# MSS_CTRL_MSS_CTRL register map
Vendor: Texas Instruments
Registers are 32-bit, read-only, reset 0x0 unless marked. A register's access mark holds for its fields unless they carry their own. Offsets are as the file gives them; [hi:lo] are bit positions; {n}, {i} and the like mark numbered series.

## MSS_CTRL_MSS_CTRL (part 5 of 5)
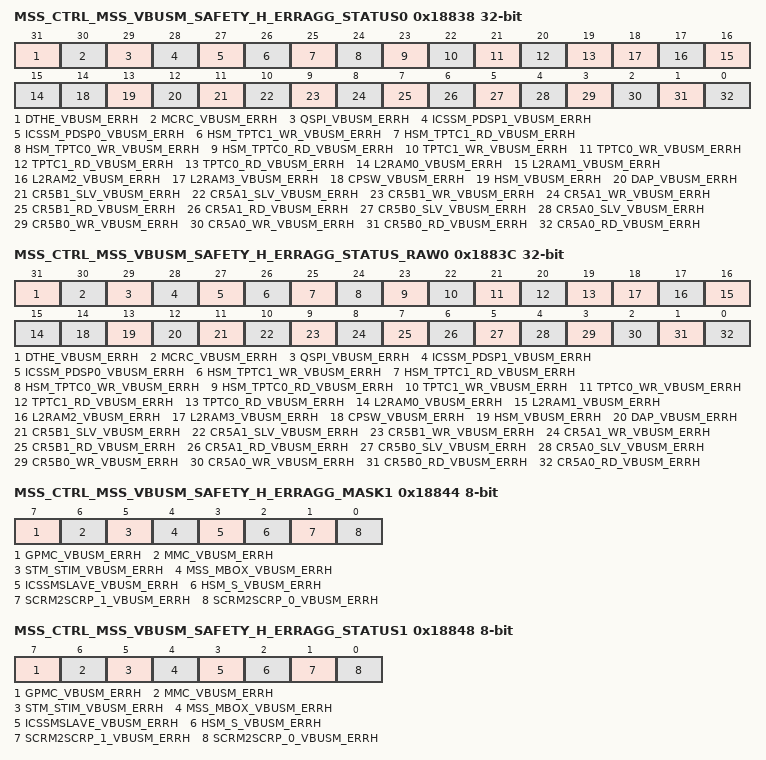
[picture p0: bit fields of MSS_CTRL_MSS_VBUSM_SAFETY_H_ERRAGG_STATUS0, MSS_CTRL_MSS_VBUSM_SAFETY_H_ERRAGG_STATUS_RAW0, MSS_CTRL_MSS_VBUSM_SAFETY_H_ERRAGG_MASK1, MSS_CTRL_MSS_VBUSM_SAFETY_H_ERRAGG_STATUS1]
0x18838 MSS_CTRL_MSS_VBUSM_SAFETY_H_ERRAGG_STATUS0 rw
  [31] DTHE_VBUSM_ERRH — Status of Error from MSS_VBUSM_SAFETY_H0_ERRAGG. Set only if Interupt is unmasked in MSS_VBUSM_SAFETY_H0_ERRAGG_ERRAGG_MASKWrie 0x1 to clear this Error.
  [30] MCRC_VBUSM_ERRH — Status of Error from MSS_VBUSM_SAFETY_H0_ERRAGG. Set only if Interupt is unmasked in MSS_VBUSM_SAFETY_H0_ERRAGG_ERRAGG_MASKWrie 0x1 to clear this Error.
  [29] QSPI_VBUSM_ERRH — Status of Error from MSS_VBUSM_SAFETY_H0_ERRAGG. Set only if Interupt is unmasked in MSS_VBUSM_SAFETY_H0_ERRAGG_ERRAGG_MASKWrie 0x1 to clear this Error.
  [28] ICSSM_PDSP1_VBUSM_ERRH — Status of Error from MSS_VBUSM_SAFETY_H0_ERRAGG. Set only if Interupt is unmasked in MSS_VBUSM_SAFETY_H0_ERRAGG_ERRAGG_MASKWrie 0x1 to clear this Error.
  [27] ICSSM_PDSP0_VBUSM_ERRH — Status of Error from MSS_VBUSM_SAFETY_H0_ERRAGG. Set only if Interupt is unmasked in MSS_VBUSM_SAFETY_H0_ERRAGG_ERRAGG_MASKWrie 0x1 to clear this Error.
  [26] HSM_TPTC1_WR_VBUSM_ERRH — Status of Error from MSS_VBUSM_SAFETY_H0_ERRAGG. Set only if Interupt is unmasked in MSS_VBUSM_SAFETY_H0_ERRAGG_ERRAGG_MASKWrie 0x1 to clear this Error.
  [25] HSM_TPTC1_RD_VBUSM_ERRH — Status of Error from MSS_VBUSM_SAFETY_H0_ERRAGG. Set only if Interupt is unmasked in MSS_VBUSM_SAFETY_H0_ERRAGG_ERRAGG_MASKWrie 0x1 to clear this Error.
  [24] HSM_TPTC0_WR_VBUSM_ERRH — Status of Error from MSS_VBUSM_SAFETY_H0_ERRAGG. Set only if Interupt is unmasked in MSS_VBUSM_SAFETY_H0_ERRAGG_ERRAGG_MASKWrie 0x1 to clear this Error.
  [23] HSM_TPTC0_RD_VBUSM_ERRH — Status of Error from MSS_VBUSM_SAFETY_H0_ERRAGG. Set only if Interupt is unmasked in MSS_VBUSM_SAFETY_H0_ERRAGG_ERRAGG_MASKWrie 0x1 to clear this Error.
  [22] TPTC1_WR_VBUSM_ERRH — Status of Error from MSS_VBUSM_SAFETY_H0_ERRAGG. Set only if Interupt is unmasked in MSS_VBUSM_SAFETY_H0_ERRAGG_ERRAGG_MASKWrie 0x1 to clear this Error.
  [21] TPTC0_WR_VBUSM_ERRH — Status of Error from MSS_VBUSM_SAFETY_H0_ERRAGG. Set only if Interupt is unmasked in MSS_VBUSM_SAFETY_H0_ERRAGG_ERRAGG_MASKWrie 0x1 to clear this Error.
  [20] TPTC1_RD_VBUSM_ERRH — Status of Error from MSS_VBUSM_SAFETY_H0_ERRAGG. Set only if Interupt is unmasked in MSS_VBUSM_SAFETY_H0_ERRAGG_ERRAGG_MASKWrie 0x1 to clear this Error.
  [19] TPTC0_RD_VBUSM_ERRH — Status of Error from MSS_VBUSM_SAFETY_H0_ERRAGG. Set only if Interupt is unmasked in MSS_VBUSM_SAFETY_H0_ERRAGG_ERRAGG_MASKWrie 0x1 to clear this Error.
  [n+15] L2RAM{n}_VBUSM_ERRH (n=0..3) — Status of Error from MSS_VBUSM_SAFETY_H0_ERRAGG. Set only if Interupt is unmasked in MSS_VBUSM_SAFETY_H0_ERRAGG_ERRAGG_MASKWrie 0x1 to clear this Error.
  [14] CPSW_VBUSM_ERRH — Status of Error from MSS_VBUSM_SAFETY_H0_ERRAGG. Set only if Interupt is unmasked in MSS_VBUSM_SAFETY_H0_ERRAGG_ERRAGG_MASKWrie 0x1 to clear this Error.
  [13] HSM_VBUSM_ERRH — Status of Error from MSS_VBUSM_SAFETY_H0_ERRAGG. Set only if Interupt is unmasked in MSS_VBUSM_SAFETY_H0_ERRAGG_ERRAGG_MASKWrie 0x1 to clear this Error.
  [12] DAP_VBUSM_ERRH — Status of Error from MSS_VBUSM_SAFETY_H0_ERRAGG. Set only if Interupt is unmasked in MSS_VBUSM_SAFETY_H0_ERRAGG_ERRAGG_MASKWrie 0x1 to clear this Error.
  [11] CR5B1_SLV_VBUSM_ERRH — Status of Error from MSS_VBUSM_SAFETY_H0_ERRAGG. Set only if Interupt is unmasked in MSS_VBUSM_SAFETY_H0_ERRAGG_ERRAGG_MASKWrie 0x1 to clear this Error.
  [10] CR5A1_SLV_VBUSM_ERRH — Status of Error from MSS_VBUSM_SAFETY_H0_ERRAGG. Set only if Interupt is unmasked in MSS_VBUSM_SAFETY_H0_ERRAGG_ERRAGG_MASKWrie 0x1 to clear this Error.
  [9] CR5B1_WR_VBUSM_ERRH — Status of Error from MSS_VBUSM_SAFETY_H0_ERRAGG. Set only if Interupt is unmasked in MSS_VBUSM_SAFETY_H0_ERRAGG_ERRAGG_MASKWrie 0x1 to clear this Error.
  [8] CR5A1_WR_VBUSM_ERRH — Status of Error from MSS_VBUSM_SAFETY_H0_ERRAGG. Set only if Interupt is unmasked in MSS_VBUSM_SAFETY_H0_ERRAGG_ERRAGG_MASKWrie 0x1 to clear this Error.
  [7] CR5B1_RD_VBUSM_ERRH — Status of Error from MSS_VBUSM_SAFETY_H0_ERRAGG. Set only if Interupt is unmasked in MSS_VBUSM_SAFETY_H0_ERRAGG_ERRAGG_MASKWrie 0x1 to clear this Error.
  [6] CR5A1_RD_VBUSM_ERRH — Status of Error from MSS_VBUSM_SAFETY_H0_ERRAGG. Set only if Interupt is unmasked in MSS_VBUSM_SAFETY_H0_ERRAGG_ERRAGG_MASKWrie 0x1 to clear this Error.
  [5] CR5B0_SLV_VBUSM_ERRH — Status of Error from MSS_VBUSM_SAFETY_H0_ERRAGG. Set only if Interupt is unmasked in MSS_VBUSM_SAFETY_H0_ERRAGG_ERRAGG_MASKWrie 0x1 to clear this Error.
  [4] CR5A0_SLV_VBUSM_ERRH — Status of Error from MSS_VBUSM_SAFETY_H0_ERRAGG. Set only if Interupt is unmasked in MSS_VBUSM_SAFETY_H0_ERRAGG_ERRAGG_MASKWrie 0x1 to clear this Error.
  [3] CR5B0_WR_VBUSM_ERRH — Status of Error from MSS_VBUSM_SAFETY_H0_ERRAGG. Set only if Interupt is unmasked in MSS_VBUSM_SAFETY_H0_ERRAGG_ERRAGG_MASKWrie 0x1 to clear this Error.
  [2] CR5A0_WR_VBUSM_ERRH — Status of Error from MSS_VBUSM_SAFETY_H0_ERRAGG. Set only if Interupt is unmasked in MSS_VBUSM_SAFETY_H0_ERRAGG_ERRAGG_MASKWrie 0x1 to clear this Error.
  [1] CR5B0_RD_VBUSM_ERRH — Status of Error from MSS_VBUSM_SAFETY_H0_ERRAGG. Set only if Interupt is unmasked in MSS_VBUSM_SAFETY_H0_ERRAGG_ERRAGG_MASKWrie 0x1 to clear this Error.
  [0] CR5A0_RD_VBUSM_ERRH — Status of Error from MSS_VBUSM_SAFETY_H0_ERRAGG. Set only if Interupt is unmasked in MSS_VBUSM_SAFETY_H0_ERRAGG_ERRAGG_MASKWrie 0x1 to clear this Error.
0x1883C MSS_CTRL_MSS_VBUSM_SAFETY_H_ERRAGG_STATUS_RAW0 rw
  [31] DTHE_VBUSM_ERRH — Raw Status of Error from MSS_VBUSM_SAFETY_H0_ERRAGG. Set irrespective if the Interupt is masked or unmasked in MSS_VBUSM_SAFETY_H0_ERRAGG_ERRAGG_MASK
  [30] MCRC_VBUSM_ERRH — Raw Status of Error from MSS_VBUSM_SAFETY_H0_ERRAGG. Set irrespective if the Interupt is masked or unmasked in MSS_VBUSM_SAFETY_H0_ERRAGG_ERRAGG_MASK
  [29] QSPI_VBUSM_ERRH — Raw Status of Error from MSS_VBUSM_SAFETY_H0_ERRAGG. Set irrespective if the Interupt is masked or unmasked in MSS_VBUSM_SAFETY_H0_ERRAGG_ERRAGG_MASK
  [28] ICSSM_PDSP1_VBUSM_ERRH — Raw Status of Error from MSS_VBUSM_SAFETY_H0_ERRAGG. Set irrespective if the Interupt is masked or unmasked in MSS_VBUSM_SAFETY_H0_ERRAGG_ERRAGG_MASK
  [27] ICSSM_PDSP0_VBUSM_ERRH — Raw Status of Error from MSS_VBUSM_SAFETY_H0_ERRAGG. Set irrespective if the Interupt is masked or unmasked in MSS_VBUSM_SAFETY_H0_ERRAGG_ERRAGG_MASK
  [26] HSM_TPTC1_WR_VBUSM_ERRH — Raw Status of Error from MSS_VBUSM_SAFETY_H0_ERRAGG. Set irrespective if the Interupt is masked or unmasked in MSS_VBUSM_SAFETY_H0_ERRAGG_ERRAGG_MASK
  [25] HSM_TPTC1_RD_VBUSM_ERRH — Raw Status of Error from MSS_VBUSM_SAFETY_H0_ERRAGG. Set irrespective if the Interupt is masked or unmasked in MSS_VBUSM_SAFETY_H0_ERRAGG_ERRAGG_MASK
  [24] HSM_TPTC0_WR_VBUSM_ERRH — Raw Status of Error from MSS_VBUSM_SAFETY_H0_ERRAGG. Set irrespective if the Interupt is masked or unmasked in MSS_VBUSM_SAFETY_H0_ERRAGG_ERRAGG_MASK
  [23] HSM_TPTC0_RD_VBUSM_ERRH — Raw Status of Error from MSS_VBUSM_SAFETY_H0_ERRAGG. Set irrespective if the Interupt is masked or unmasked in MSS_VBUSM_SAFETY_H0_ERRAGG_ERRAGG_MASK
  [22] TPTC1_WR_VBUSM_ERRH — Raw Status of Error from MSS_VBUSM_SAFETY_H0_ERRAGG. Set irrespective if the Interupt is masked or unmasked in MSS_VBUSM_SAFETY_H0_ERRAGG_ERRAGG_MASK
  [21] TPTC0_WR_VBUSM_ERRH — Raw Status of Error from MSS_VBUSM_SAFETY_H0_ERRAGG. Set irrespective if the Interupt is masked or unmasked in MSS_VBUSM_SAFETY_H0_ERRAGG_ERRAGG_MASK
  [20] TPTC1_RD_VBUSM_ERRH — Raw Status of Error from MSS_VBUSM_SAFETY_H0_ERRAGG. Set irrespective if the Interupt is masked or unmasked in MSS_VBUSM_SAFETY_H0_ERRAGG_ERRAGG_MASK
  [19] TPTC0_RD_VBUSM_ERRH — Raw Status of Error from MSS_VBUSM_SAFETY_H0_ERRAGG. Set irrespective if the Interupt is masked or unmasked in MSS_VBUSM_SAFETY_H0_ERRAGG_ERRAGG_MASK
  [n+15] L2RAM{n}_VBUSM_ERRH (n=0..3) — Raw Status of Error from MSS_VBUSM_SAFETY_H0_ERRAGG. Set irrespective if the Interupt is masked or unmasked in MSS_VBUSM_SAFETY_H0_ERRAGG_ERRAGG_MASK
  [14] CPSW_VBUSM_ERRH — Raw Status of Error from MSS_VBUSM_SAFETY_H0_ERRAGG. Set irrespective if the Interupt is masked or unmasked in MSS_VBUSM_SAFETY_H0_ERRAGG_ERRAGG_MASK
  [13] HSM_VBUSM_ERRH — Raw Status of Error from MSS_VBUSM_SAFETY_H0_ERRAGG. Set irrespective if the Interupt is masked or unmasked in MSS_VBUSM_SAFETY_H0_ERRAGG_ERRAGG_MASK
  [12] DAP_VBUSM_ERRH — Raw Status of Error from MSS_VBUSM_SAFETY_H0_ERRAGG. Set irrespective if the Interupt is masked or unmasked in MSS_VBUSM_SAFETY_H0_ERRAGG_ERRAGG_MASK
  [11] CR5B1_SLV_VBUSM_ERRH — Raw Status of Error from MSS_VBUSM_SAFETY_H0_ERRAGG. Set irrespective if the Interupt is masked or unmasked in MSS_VBUSM_SAFETY_H0_ERRAGG_ERRAGG_MASK
  [10] CR5A1_SLV_VBUSM_ERRH — Raw Status of Error from MSS_VBUSM_SAFETY_H0_ERRAGG. Set irrespective if the Interupt is masked or unmasked in MSS_VBUSM_SAFETY_H0_ERRAGG_ERRAGG_MASK
  [9] CR5B1_WR_VBUSM_ERRH — Raw Status of Error from MSS_VBUSM_SAFETY_H0_ERRAGG. Set irrespective if the Interupt is masked or unmasked in MSS_VBUSM_SAFETY_H0_ERRAGG_ERRAGG_MASK
  [8] CR5A1_WR_VBUSM_ERRH — Raw Status of Error from MSS_VBUSM_SAFETY_H0_ERRAGG. Set irrespective if the Interupt is masked or unmasked in MSS_VBUSM_SAFETY_H0_ERRAGG_ERRAGG_MASK
  [7] CR5B1_RD_VBUSM_ERRH — Raw Status of Error from MSS_VBUSM_SAFETY_H0_ERRAGG. Set irrespective if the Interupt is masked or unmasked in MSS_VBUSM_SAFETY_H0_ERRAGG_ERRAGG_MASK
  [6] CR5A1_RD_VBUSM_ERRH — Raw Status of Error from MSS_VBUSM_SAFETY_H0_ERRAGG. Set irrespective if the Interupt is masked or unmasked in MSS_VBUSM_SAFETY_H0_ERRAGG_ERRAGG_MASK
  [5] CR5B0_SLV_VBUSM_ERRH — Raw Status of Error from MSS_VBUSM_SAFETY_H0_ERRAGG. Set irrespective if the Interupt is masked or unmasked in MSS_VBUSM_SAFETY_H0_ERRAGG_ERRAGG_MASK
  [4] CR5A0_SLV_VBUSM_ERRH — Raw Status of Error from MSS_VBUSM_SAFETY_H0_ERRAGG. Set irrespective if the Interupt is masked or unmasked in MSS_VBUSM_SAFETY_H0_ERRAGG_ERRAGG_MASK
  [3] CR5B0_WR_VBUSM_ERRH — Raw Status of Error from MSS_VBUSM_SAFETY_H0_ERRAGG. Set irrespective if the Interupt is masked or unmasked in MSS_VBUSM_SAFETY_H0_ERRAGG_ERRAGG_MASK
  [2] CR5A0_WR_VBUSM_ERRH — Raw Status of Error from MSS_VBUSM_SAFETY_H0_ERRAGG. Set irrespective if the Interupt is masked or unmasked in MSS_VBUSM_SAFETY_H0_ERRAGG_ERRAGG_MASK
  [1] CR5B0_RD_VBUSM_ERRH — Raw Status of Error from MSS_VBUSM_SAFETY_H0_ERRAGG. Set irrespective if the Interupt is masked or unmasked in MSS_VBUSM_SAFETY_H0_ERRAGG_ERRAGG_MASK
  [0] CR5A0_RD_VBUSM_ERRH — Raw Status of Error from MSS_VBUSM_SAFETY_H0_ERRAGG. Set irrespective if the Interupt is masked or unmasked in MSS_VBUSM_SAFETY_H0_ERRAGG_ERRAGG_MASK
0x18844 MSS_CTRL_MSS_VBUSM_SAFETY_H_ERRAGG_MASK1 8-bit rw
  [7] GPMC_VBUSM_ERRH — Mask Error from MSS_VBUSM_SAFETY_H1_ERRAGG to aggregated Error MSS_VBUSM_SAFETY_H1_ERRAGG_ERRAGG1 : Error is Masked0 : Error is Unmasked
  [6] MMC_VBUSM_ERRH — Mask Error from MSS_VBUSM_SAFETY_H1_ERRAGG to aggregated Error MSS_VBUSM_SAFETY_H1_ERRAGG_ERRAGG1 : Error is Masked0 : Error is Unmasked
  [5] STM_STIM_VBUSM_ERRH — Mask Error from MSS_VBUSM_SAFETY_H1_ERRAGG to aggregated Error MSS_VBUSM_SAFETY_H1_ERRAGG_ERRAGG1 : Error is Masked0 : Error is Unmasked
  [4] MSS_MBOX_VBUSM_ERRH — Mask Error from MSS_VBUSM_SAFETY_H1_ERRAGG to aggregated Error MSS_VBUSM_SAFETY_H1_ERRAGG_ERRAGG1 : Error is Masked0 : Error is Unmasked
  [3] ICSSMSLAVE_VBUSM_ERRH — Mask Error from MSS_VBUSM_SAFETY_H1_ERRAGG to aggregated Error MSS_VBUSM_SAFETY_H1_ERRAGG_ERRAGG1 : Error is Masked0 : Error is Unmasked
  [2] HSM_S_VBUSM_ERRH — Mask Error from MSS_VBUSM_SAFETY_H1_ERRAGG to aggregated Error MSS_VBUSM_SAFETY_H1_ERRAGG_ERRAGG1 : Error is Masked0 : Error is Unmasked
  [1] SCRM2SCRP_1_VBUSM_ERRH — Mask Error from MSS_VBUSM_SAFETY_H1_ERRAGG to aggregated Error MSS_VBUSM_SAFETY_H1_ERRAGG_ERRAGG1 : Error is Masked0 : Error is Unmasked
  [0] SCRM2SCRP_0_VBUSM_ERRH — Mask Error from MSS_VBUSM_SAFETY_H1_ERRAGG to aggregated Error MSS_VBUSM_SAFETY_H1_ERRAGG_ERRAGG1 : Error is Masked0 : Error is Unmasked
0x18848 MSS_CTRL_MSS_VBUSM_SAFETY_H_ERRAGG_STATUS1 8-bit rw
  [7] GPMC_VBUSM_ERRH — Status of Error from MSS_VBUSM_SAFETY_H1_ERRAGG. Set only if Interupt is unmasked in MSS_VBUSM_SAFETY_H1_ERRAGG_ERRAGG_MASKWrie 0x1 to clear this Error.
  [6] MMC_VBUSM_ERRH — Status of Error from MSS_VBUSM_SAFETY_H1_ERRAGG. Set only if Interupt is unmasked in MSS_VBUSM_SAFETY_H1_ERRAGG_ERRAGG_MASKWrie 0x1 to clear this Error.
  [5] STM_STIM_VBUSM_ERRH — Status of Error from MSS_VBUSM_SAFETY_H1_ERRAGG. Set only if Interupt is unmasked in MSS_VBUSM_SAFETY_H1_ERRAGG_ERRAGG_MASKWrie 0x1 to clear this Error.
  [4] MSS_MBOX_VBUSM_ERRH — Status of Error from MSS_VBUSM_SAFETY_H1_ERRAGG. Set only if Interupt is unmasked in MSS_VBUSM_SAFETY_H1_ERRAGG_ERRAGG_MASKWrie 0x1 to clear this Error.
  [3] ICSSMSLAVE_VBUSM_ERRH — Status of Error from MSS_VBUSM_SAFETY_H1_ERRAGG. Set only if Interupt is unmasked in MSS_VBUSM_SAFETY_H1_ERRAGG_ERRAGG_MASKWrie 0x1 to clear this Error.
  [2] HSM_S_VBUSM_ERRH — Status of Error from MSS_VBUSM_SAFETY_H1_ERRAGG. Set only if Interupt is unmasked in MSS_VBUSM_SAFETY_H1_ERRAGG_ERRAGG_MASKWrie 0x1 to clear this Error.
  [1] SCRM2SCRP_1_VBUSM_ERRH — Status of Error from MSS_VBUSM_SAFETY_H1_ERRAGG. Set only if Interupt is unmasked in MSS_VBUSM_SAFETY_H1_ERRAGG_ERRAGG_MASKWrie 0x1 to clear this Error.
  [0] SCRM2SCRP_0_VBUSM_ERRH — Status of Error from MSS_VBUSM_SAFETY_H1_ERRAGG. Set only if Interupt is unmasked in MSS_VBUSM_SAFETY_H1_ERRAGG_ERRAGG_MASKWrie 0x1 to clear this Error.
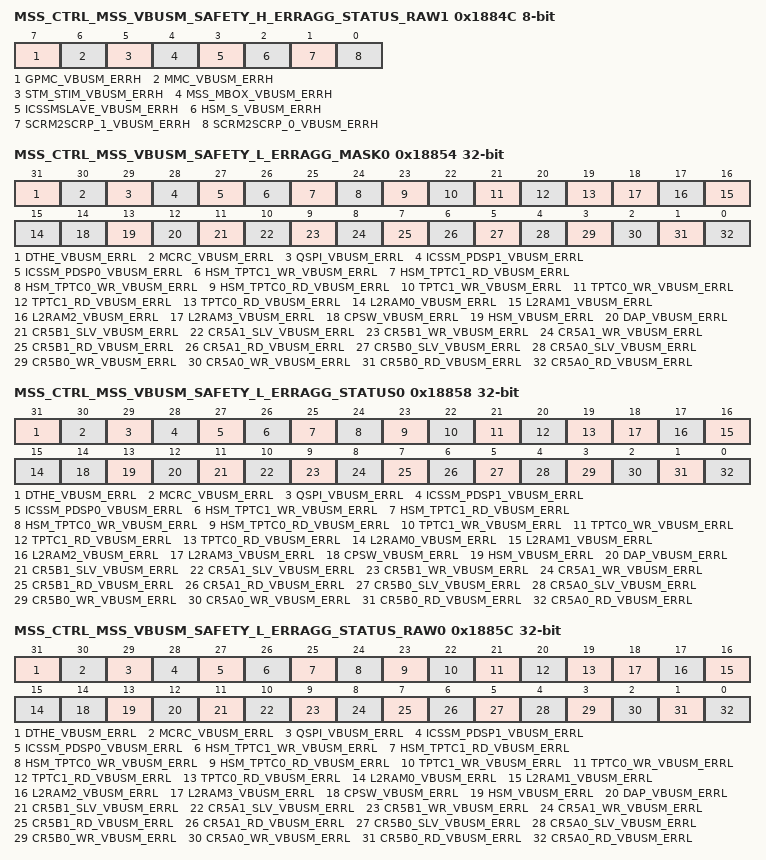
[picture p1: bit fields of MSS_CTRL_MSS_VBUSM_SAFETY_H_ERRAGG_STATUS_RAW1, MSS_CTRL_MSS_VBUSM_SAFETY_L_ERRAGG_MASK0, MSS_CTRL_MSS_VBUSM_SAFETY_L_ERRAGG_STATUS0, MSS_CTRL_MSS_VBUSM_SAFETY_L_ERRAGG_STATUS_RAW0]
0x1884C MSS_CTRL_MSS_VBUSM_SAFETY_H_ERRAGG_STATUS_RAW1 8-bit rw
  [7] GPMC_VBUSM_ERRH — Raw Status of Error from MSS_VBUSM_SAFETY_H1_ERRAGG. Set irrespective if the Interupt is masked or unmasked in MSS_VBUSM_SAFETY_H1_ERRAGG_ERRAGG_MASK
  [6] MMC_VBUSM_ERRH — Raw Status of Error from MSS_VBUSM_SAFETY_H1_ERRAGG. Set irrespective if the Interupt is masked or unmasked in MSS_VBUSM_SAFETY_H1_ERRAGG_ERRAGG_MASK
  [5] STM_STIM_VBUSM_ERRH — Raw Status of Error from MSS_VBUSM_SAFETY_H1_ERRAGG. Set irrespective if the Interupt is masked or unmasked in MSS_VBUSM_SAFETY_H1_ERRAGG_ERRAGG_MASK
  [4] MSS_MBOX_VBUSM_ERRH — Raw Status of Error from MSS_VBUSM_SAFETY_H1_ERRAGG. Set irrespective if the Interupt is masked or unmasked in MSS_VBUSM_SAFETY_H1_ERRAGG_ERRAGG_MASK
  [3] ICSSMSLAVE_VBUSM_ERRH — Raw Status of Error from MSS_VBUSM_SAFETY_H1_ERRAGG. Set irrespective if the Interupt is masked or unmasked in MSS_VBUSM_SAFETY_H1_ERRAGG_ERRAGG_MASK
  [2] HSM_S_VBUSM_ERRH — Raw Status of Error from MSS_VBUSM_SAFETY_H1_ERRAGG. Set irrespective if the Interupt is masked or unmasked in MSS_VBUSM_SAFETY_H1_ERRAGG_ERRAGG_MASK
  [1] SCRM2SCRP_1_VBUSM_ERRH — Raw Status of Error from MSS_VBUSM_SAFETY_H1_ERRAGG. Set irrespective if the Interupt is masked or unmasked in MSS_VBUSM_SAFETY_H1_ERRAGG_ERRAGG_MASK
  [0] SCRM2SCRP_0_VBUSM_ERRH — Raw Status of Error from MSS_VBUSM_SAFETY_H1_ERRAGG. Set irrespective if the Interupt is masked or unmasked in MSS_VBUSM_SAFETY_H1_ERRAGG_ERRAGG_MASK
0x18854 MSS_CTRL_MSS_VBUSM_SAFETY_L_ERRAGG_MASK0 rw
  [31] DTHE_VBUSM_ERRL — Mask Error from MSS_VBUSM_SAFETY_L0_ERRAGG to aggregated Error MSS_VBUSM_SAFETY_L0_ERRAGG_ERRAGG1 : Error is Masked0 : Error is Unmasked
  [30] MCRC_VBUSM_ERRL — Mask Error from MSS_VBUSM_SAFETY_L0_ERRAGG to aggregated Error MSS_VBUSM_SAFETY_L0_ERRAGG_ERRAGG1 : Error is Masked0 : Error is Unmasked
  [29] QSPI_VBUSM_ERRL — Mask Error from MSS_VBUSM_SAFETY_L0_ERRAGG to aggregated Error MSS_VBUSM_SAFETY_L0_ERRAGG_ERRAGG1 : Error is Masked0 : Error is Unmasked
  [28] ICSSM_PDSP1_VBUSM_ERRL — Mask Error from MSS_VBUSM_SAFETY_L0_ERRAGG to aggregated Error MSS_VBUSM_SAFETY_L0_ERRAGG_ERRAGG1 : Error is Masked0 : Error is Unmasked
  [27] ICSSM_PDSP0_VBUSM_ERRL — Mask Error from MSS_VBUSM_SAFETY_L0_ERRAGG to aggregated Error MSS_VBUSM_SAFETY_L0_ERRAGG_ERRAGG1 : Error is Masked0 : Error is Unmasked
  [26] HSM_TPTC1_WR_VBUSM_ERRL — Mask Error from MSS_VBUSM_SAFETY_L0_ERRAGG to aggregated Error MSS_VBUSM_SAFETY_L0_ERRAGG_ERRAGG1 : Error is Masked0 : Error is Unmasked
  [25] HSM_TPTC1_RD_VBUSM_ERRL — Mask Error from MSS_VBUSM_SAFETY_L0_ERRAGG to aggregated Error MSS_VBUSM_SAFETY_L0_ERRAGG_ERRAGG1 : Error is Masked0 : Error is Unmasked
  [24] HSM_TPTC0_WR_VBUSM_ERRL — Mask Error from MSS_VBUSM_SAFETY_L0_ERRAGG to aggregated Error MSS_VBUSM_SAFETY_L0_ERRAGG_ERRAGG1 : Error is Masked0 : Error is Unmasked
  [23] HSM_TPTC0_RD_VBUSM_ERRL — Mask Error from MSS_VBUSM_SAFETY_L0_ERRAGG to aggregated Error MSS_VBUSM_SAFETY_L0_ERRAGG_ERRAGG1 : Error is Masked0 : Error is Unmasked
  [22] TPTC1_WR_VBUSM_ERRL — Mask Error from MSS_VBUSM_SAFETY_L0_ERRAGG to aggregated Error MSS_VBUSM_SAFETY_L0_ERRAGG_ERRAGG1 : Error is Masked0 : Error is Unmasked
  [21] TPTC0_WR_VBUSM_ERRL — Mask Error from MSS_VBUSM_SAFETY_L0_ERRAGG to aggregated Error MSS_VBUSM_SAFETY_L0_ERRAGG_ERRAGG1 : Error is Masked0 : Error is Unmasked
  [20] TPTC1_RD_VBUSM_ERRL — Mask Error from MSS_VBUSM_SAFETY_L0_ERRAGG to aggregated Error MSS_VBUSM_SAFETY_L0_ERRAGG_ERRAGG1 : Error is Masked0 : Error is Unmasked
  [19] TPTC0_RD_VBUSM_ERRL — Mask Error from MSS_VBUSM_SAFETY_L0_ERRAGG to aggregated Error MSS_VBUSM_SAFETY_L0_ERRAGG_ERRAGG1 : Error is Masked0 : Error is Unmasked
  [n+15] L2RAM{n}_VBUSM_ERRL (n=0..3) — Mask Error from MSS_VBUSM_SAFETY_L0_ERRAGG to aggregated Error MSS_VBUSM_SAFETY_L0_ERRAGG_ERRAGG1 : Error is Masked0 : Error is Unmasked
  [14] CPSW_VBUSM_ERRL — Mask Error from MSS_VBUSM_SAFETY_L0_ERRAGG to aggregated Error MSS_VBUSM_SAFETY_L0_ERRAGG_ERRAGG1 : Error is Masked0 : Error is Unmasked
  [13] HSM_VBUSM_ERRL — Mask Error from MSS_VBUSM_SAFETY_L0_ERRAGG to aggregated Error MSS_VBUSM_SAFETY_L0_ERRAGG_ERRAGG1 : Error is Masked0 : Error is Unmasked
  [12] DAP_VBUSM_ERRL — Mask Error from MSS_VBUSM_SAFETY_L0_ERRAGG to aggregated Error MSS_VBUSM_SAFETY_L0_ERRAGG_ERRAGG1 : Error is Masked0 : Error is Unmasked
  [11] CR5B1_SLV_VBUSM_ERRL — Mask Error from MSS_VBUSM_SAFETY_L0_ERRAGG to aggregated Error MSS_VBUSM_SAFETY_L0_ERRAGG_ERRAGG1 : Error is Masked0 : Error is Unmasked
  [10] CR5A1_SLV_VBUSM_ERRL — Mask Error from MSS_VBUSM_SAFETY_L0_ERRAGG to aggregated Error MSS_VBUSM_SAFETY_L0_ERRAGG_ERRAGG1 : Error is Masked0 : Error is Unmasked
  [9] CR5B1_WR_VBUSM_ERRL — Mask Error from MSS_VBUSM_SAFETY_L0_ERRAGG to aggregated Error MSS_VBUSM_SAFETY_L0_ERRAGG_ERRAGG1 : Error is Masked0 : Error is Unmasked
  [8] CR5A1_WR_VBUSM_ERRL — Mask Error from MSS_VBUSM_SAFETY_L0_ERRAGG to aggregated Error MSS_VBUSM_SAFETY_L0_ERRAGG_ERRAGG1 : Error is Masked0 : Error is Unmasked
  [7] CR5B1_RD_VBUSM_ERRL — Mask Error from MSS_VBUSM_SAFETY_L0_ERRAGG to aggregated Error MSS_VBUSM_SAFETY_L0_ERRAGG_ERRAGG1 : Error is Masked0 : Error is Unmasked
  [6] CR5A1_RD_VBUSM_ERRL — Mask Error from MSS_VBUSM_SAFETY_L0_ERRAGG to aggregated Error MSS_VBUSM_SAFETY_L0_ERRAGG_ERRAGG1 : Error is Masked0 : Error is Unmasked
  [5] CR5B0_SLV_VBUSM_ERRL — Mask Error from MSS_VBUSM_SAFETY_L0_ERRAGG to aggregated Error MSS_VBUSM_SAFETY_L0_ERRAGG_ERRAGG1 : Error is Masked0 : Error is Unmasked
  [4] CR5A0_SLV_VBUSM_ERRL — Mask Error from MSS_VBUSM_SAFETY_L0_ERRAGG to aggregated Error MSS_VBUSM_SAFETY_L0_ERRAGG_ERRAGG1 : Error is Masked0 : Error is Unmasked
  [3] CR5B0_WR_VBUSM_ERRL — Mask Error from MSS_VBUSM_SAFETY_L0_ERRAGG to aggregated Error MSS_VBUSM_SAFETY_L0_ERRAGG_ERRAGG1 : Error is Masked0 : Error is Unmasked
  [2] CR5A0_WR_VBUSM_ERRL — Mask Error from MSS_VBUSM_SAFETY_L0_ERRAGG to aggregated Error MSS_VBUSM_SAFETY_L0_ERRAGG_ERRAGG1 : Error is Masked0 : Error is Unmasked
  [1] CR5B0_RD_VBUSM_ERRL — Mask Error from MSS_VBUSM_SAFETY_L0_ERRAGG to aggregated Error MSS_VBUSM_SAFETY_L0_ERRAGG_ERRAGG1 : Error is Masked0 : Error is Unmasked
  [0] CR5A0_RD_VBUSM_ERRL — Mask Error from MSS_VBUSM_SAFETY_L0_ERRAGG to aggregated Error MSS_VBUSM_SAFETY_L0_ERRAGG_ERRAGG1 : Error is Masked0 : Error is Unmasked
0x18858 MSS_CTRL_MSS_VBUSM_SAFETY_L_ERRAGG_STATUS0 rw
  [31] DTHE_VBUSM_ERRL — Status of Error from MSS_VBUSM_SAFETY_L0_ERRAGG. Set only if Interupt is unmasked in MSS_VBUSM_SAFETY_L0_ERRAGG_ERRAGG_MASKWrie 0x1 to clear this Error.
  [30] MCRC_VBUSM_ERRL — Status of Error from MSS_VBUSM_SAFETY_L0_ERRAGG. Set only if Interupt is unmasked in MSS_VBUSM_SAFETY_L0_ERRAGG_ERRAGG_MASKWrie 0x1 to clear this Error.
  [29] QSPI_VBUSM_ERRL — Status of Error from MSS_VBUSM_SAFETY_L0_ERRAGG. Set only if Interupt is unmasked in MSS_VBUSM_SAFETY_L0_ERRAGG_ERRAGG_MASKWrie 0x1 to clear this Error.
  [28] ICSSM_PDSP1_VBUSM_ERRL — Status of Error from MSS_VBUSM_SAFETY_L0_ERRAGG. Set only if Interupt is unmasked in MSS_VBUSM_SAFETY_L0_ERRAGG_ERRAGG_MASKWrie 0x1 to clear this Error.
  [27] ICSSM_PDSP0_VBUSM_ERRL — Status of Error from MSS_VBUSM_SAFETY_L0_ERRAGG. Set only if Interupt is unmasked in MSS_VBUSM_SAFETY_L0_ERRAGG_ERRAGG_MASKWrie 0x1 to clear this Error.
  [26] HSM_TPTC1_WR_VBUSM_ERRL — Status of Error from MSS_VBUSM_SAFETY_L0_ERRAGG. Set only if Interupt is unmasked in MSS_VBUSM_SAFETY_L0_ERRAGG_ERRAGG_MASKWrie 0x1 to clear this Error.
  [25] HSM_TPTC1_RD_VBUSM_ERRL — Status of Error from MSS_VBUSM_SAFETY_L0_ERRAGG. Set only if Interupt is unmasked in MSS_VBUSM_SAFETY_L0_ERRAGG_ERRAGG_MASKWrie 0x1 to clear this Error.
  [24] HSM_TPTC0_WR_VBUSM_ERRL — Status of Error from MSS_VBUSM_SAFETY_L0_ERRAGG. Set only if Interupt is unmasked in MSS_VBUSM_SAFETY_L0_ERRAGG_ERRAGG_MASKWrie 0x1 to clear this Error.
  [23] HSM_TPTC0_RD_VBUSM_ERRL — Status of Error from MSS_VBUSM_SAFETY_L0_ERRAGG. Set only if Interupt is unmasked in MSS_VBUSM_SAFETY_L0_ERRAGG_ERRAGG_MASKWrie 0x1 to clear this Error.
  [22] TPTC1_WR_VBUSM_ERRL — Status of Error from MSS_VBUSM_SAFETY_L0_ERRAGG. Set only if Interupt is unmasked in MSS_VBUSM_SAFETY_L0_ERRAGG_ERRAGG_MASKWrie 0x1 to clear this Error.
  [21] TPTC0_WR_VBUSM_ERRL — Status of Error from MSS_VBUSM_SAFETY_L0_ERRAGG. Set only if Interupt is unmasked in MSS_VBUSM_SAFETY_L0_ERRAGG_ERRAGG_MASKWrie 0x1 to clear this Error.
  [20] TPTC1_RD_VBUSM_ERRL — Status of Error from MSS_VBUSM_SAFETY_L0_ERRAGG. Set only if Interupt is unmasked in MSS_VBUSM_SAFETY_L0_ERRAGG_ERRAGG_MASKWrie 0x1 to clear this Error.
  [19] TPTC0_RD_VBUSM_ERRL — Status of Error from MSS_VBUSM_SAFETY_L0_ERRAGG. Set only if Interupt is unmasked in MSS_VBUSM_SAFETY_L0_ERRAGG_ERRAGG_MASKWrie 0x1 to clear this Error.
  [n+15] L2RAM{n}_VBUSM_ERRL (n=0..3) — Status of Error from MSS_VBUSM_SAFETY_L0_ERRAGG. Set only if Interupt is unmasked in MSS_VBUSM_SAFETY_L0_ERRAGG_ERRAGG_MASKWrie 0x1 to clear this Error.
  [14] CPSW_VBUSM_ERRL — Status of Error from MSS_VBUSM_SAFETY_L0_ERRAGG. Set only if Interupt is unmasked in MSS_VBUSM_SAFETY_L0_ERRAGG_ERRAGG_MASKWrie 0x1 to clear this Error.
  [13] HSM_VBUSM_ERRL — Status of Error from MSS_VBUSM_SAFETY_L0_ERRAGG. Set only if Interupt is unmasked in MSS_VBUSM_SAFETY_L0_ERRAGG_ERRAGG_MASKWrie 0x1 to clear this Error.
  [12] DAP_VBUSM_ERRL — Status of Error from MSS_VBUSM_SAFETY_L0_ERRAGG. Set only if Interupt is unmasked in MSS_VBUSM_SAFETY_L0_ERRAGG_ERRAGG_MASKWrie 0x1 to clear this Error.
  [11] CR5B1_SLV_VBUSM_ERRL — Status of Error from MSS_VBUSM_SAFETY_L0_ERRAGG. Set only if Interupt is unmasked in MSS_VBUSM_SAFETY_L0_ERRAGG_ERRAGG_MASKWrie 0x1 to clear this Error.
  [10] CR5A1_SLV_VBUSM_ERRL — Status of Error from MSS_VBUSM_SAFETY_L0_ERRAGG. Set only if Interupt is unmasked in MSS_VBUSM_SAFETY_L0_ERRAGG_ERRAGG_MASKWrie 0x1 to clear this Error.
  [9] CR5B1_WR_VBUSM_ERRL — Status of Error from MSS_VBUSM_SAFETY_L0_ERRAGG. Set only if Interupt is unmasked in MSS_VBUSM_SAFETY_L0_ERRAGG_ERRAGG_MASKWrie 0x1 to clear this Error.
  [8] CR5A1_WR_VBUSM_ERRL — Status of Error from MSS_VBUSM_SAFETY_L0_ERRAGG. Set only if Interupt is unmasked in MSS_VBUSM_SAFETY_L0_ERRAGG_ERRAGG_MASKWrie 0x1 to clear this Error.
  [7] CR5B1_RD_VBUSM_ERRL — Status of Error from MSS_VBUSM_SAFETY_L0_ERRAGG. Set only if Interupt is unmasked in MSS_VBUSM_SAFETY_L0_ERRAGG_ERRAGG_MASKWrie 0x1 to clear this Error.
  [6] CR5A1_RD_VBUSM_ERRL — Status of Error from MSS_VBUSM_SAFETY_L0_ERRAGG. Set only if Interupt is unmasked in MSS_VBUSM_SAFETY_L0_ERRAGG_ERRAGG_MASKWrie 0x1 to clear this Error.
  [5] CR5B0_SLV_VBUSM_ERRL — Status of Error from MSS_VBUSM_SAFETY_L0_ERRAGG. Set only if Interupt is unmasked in MSS_VBUSM_SAFETY_L0_ERRAGG_ERRAGG_MASKWrie 0x1 to clear this Error.
  [4] CR5A0_SLV_VBUSM_ERRL — Status of Error from MSS_VBUSM_SAFETY_L0_ERRAGG. Set only if Interupt is unmasked in MSS_VBUSM_SAFETY_L0_ERRAGG_ERRAGG_MASKWrie 0x1 to clear this Error.
  [3] CR5B0_WR_VBUSM_ERRL — Status of Error from MSS_VBUSM_SAFETY_L0_ERRAGG. Set only if Interupt is unmasked in MSS_VBUSM_SAFETY_L0_ERRAGG_ERRAGG_MASKWrie 0x1 to clear this Error.
  [2] CR5A0_WR_VBUSM_ERRL — Status of Error from MSS_VBUSM_SAFETY_L0_ERRAGG. Set only if Interupt is unmasked in MSS_VBUSM_SAFETY_L0_ERRAGG_ERRAGG_MASKWrie 0x1 to clear this Error.
  [1] CR5B0_RD_VBUSM_ERRL — Status of Error from MSS_VBUSM_SAFETY_L0_ERRAGG. Set only if Interupt is unmasked in MSS_VBUSM_SAFETY_L0_ERRAGG_ERRAGG_MASKWrie 0x1 to clear this Error.
  [0] CR5A0_RD_VBUSM_ERRL — Status of Error from MSS_VBUSM_SAFETY_L0_ERRAGG. Set only if Interupt is unmasked in MSS_VBUSM_SAFETY_L0_ERRAGG_ERRAGG_MASKWrie 0x1 to clear this Error.
0x1885C MSS_CTRL_MSS_VBUSM_SAFETY_L_ERRAGG_STATUS_RAW0 rw
  [31] DTHE_VBUSM_ERRL — Raw Status of Error from MSS_VBUSM_SAFETY_L0_ERRAGG. Set irrespective if the Interupt is masked or unmasked in MSS_VBUSM_SAFETY_L0_ERRAGG_ERRAGG_MASK
  [30] MCRC_VBUSM_ERRL — Raw Status of Error from MSS_VBUSM_SAFETY_L0_ERRAGG. Set irrespective if the Interupt is masked or unmasked in MSS_VBUSM_SAFETY_L0_ERRAGG_ERRAGG_MASK
  [29] QSPI_VBUSM_ERRL — Raw Status of Error from MSS_VBUSM_SAFETY_L0_ERRAGG. Set irrespective if the Interupt is masked or unmasked in MSS_VBUSM_SAFETY_L0_ERRAGG_ERRAGG_MASK
  [28] ICSSM_PDSP1_VBUSM_ERRL — Raw Status of Error from MSS_VBUSM_SAFETY_L0_ERRAGG. Set irrespective if the Interupt is masked or unmasked in MSS_VBUSM_SAFETY_L0_ERRAGG_ERRAGG_MASK
  [27] ICSSM_PDSP0_VBUSM_ERRL — Raw Status of Error from MSS_VBUSM_SAFETY_L0_ERRAGG. Set irrespective if the Interupt is masked or unmasked in MSS_VBUSM_SAFETY_L0_ERRAGG_ERRAGG_MASK
  [26] HSM_TPTC1_WR_VBUSM_ERRL — Raw Status of Error from MSS_VBUSM_SAFETY_L0_ERRAGG. Set irrespective if the Interupt is masked or unmasked in MSS_VBUSM_SAFETY_L0_ERRAGG_ERRAGG_MASK
  [25] HSM_TPTC1_RD_VBUSM_ERRL — Raw Status of Error from MSS_VBUSM_SAFETY_L0_ERRAGG. Set irrespective if the Interupt is masked or unmasked in MSS_VBUSM_SAFETY_L0_ERRAGG_ERRAGG_MASK
  [24] HSM_TPTC0_WR_VBUSM_ERRL — Raw Status of Error from MSS_VBUSM_SAFETY_L0_ERRAGG. Set irrespective if the Interupt is masked or unmasked in MSS_VBUSM_SAFETY_L0_ERRAGG_ERRAGG_MASK
  [23] HSM_TPTC0_RD_VBUSM_ERRL — Raw Status of Error from MSS_VBUSM_SAFETY_L0_ERRAGG. Set irrespective if the Interupt is masked or unmasked in MSS_VBUSM_SAFETY_L0_ERRAGG_ERRAGG_MASK
  [22] TPTC1_WR_VBUSM_ERRL — Raw Status of Error from MSS_VBUSM_SAFETY_L0_ERRAGG. Set irrespective if the Interupt is masked or unmasked in MSS_VBUSM_SAFETY_L0_ERRAGG_ERRAGG_MASK
  [21] TPTC0_WR_VBUSM_ERRL — Raw Status of Error from MSS_VBUSM_SAFETY_L0_ERRAGG. Set irrespective if the Interupt is masked or unmasked in MSS_VBUSM_SAFETY_L0_ERRAGG_ERRAGG_MASK
  [20] TPTC1_RD_VBUSM_ERRL — Raw Status of Error from MSS_VBUSM_SAFETY_L0_ERRAGG. Set irrespective if the Interupt is masked or unmasked in MSS_VBUSM_SAFETY_L0_ERRAGG_ERRAGG_MASK
  [19] TPTC0_RD_VBUSM_ERRL — Raw Status of Error from MSS_VBUSM_SAFETY_L0_ERRAGG. Set irrespective if the Interupt is masked or unmasked in MSS_VBUSM_SAFETY_L0_ERRAGG_ERRAGG_MASK
  [n+15] L2RAM{n}_VBUSM_ERRL (n=0..3) — Raw Status of Error from MSS_VBUSM_SAFETY_L0_ERRAGG. Set irrespective if the Interupt is masked or unmasked in MSS_VBUSM_SAFETY_L0_ERRAGG_ERRAGG_MASK
  [14] CPSW_VBUSM_ERRL — Raw Status of Error from MSS_VBUSM_SAFETY_L0_ERRAGG. Set irrespective if the Interupt is masked or unmasked in MSS_VBUSM_SAFETY_L0_ERRAGG_ERRAGG_MASK
  [13] HSM_VBUSM_ERRL — Raw Status of Error from MSS_VBUSM_SAFETY_L0_ERRAGG. Set irrespective if the Interupt is masked or unmasked in MSS_VBUSM_SAFETY_L0_ERRAGG_ERRAGG_MASK
  [12] DAP_VBUSM_ERRL — Raw Status of Error from MSS_VBUSM_SAFETY_L0_ERRAGG. Set irrespective if the Interupt is masked or unmasked in MSS_VBUSM_SAFETY_L0_ERRAGG_ERRAGG_MASK
  [11] CR5B1_SLV_VBUSM_ERRL — Raw Status of Error from MSS_VBUSM_SAFETY_L0_ERRAGG. Set irrespective if the Interupt is masked or unmasked in MSS_VBUSM_SAFETY_L0_ERRAGG_ERRAGG_MASK
  [10] CR5A1_SLV_VBUSM_ERRL — Raw Status of Error from MSS_VBUSM_SAFETY_L0_ERRAGG. Set irrespective if the Interupt is masked or unmasked in MSS_VBUSM_SAFETY_L0_ERRAGG_ERRAGG_MASK
  [9] CR5B1_WR_VBUSM_ERRL — Raw Status of Error from MSS_VBUSM_SAFETY_L0_ERRAGG. Set irrespective if the Interupt is masked or unmasked in MSS_VBUSM_SAFETY_L0_ERRAGG_ERRAGG_MASK
  [8] CR5A1_WR_VBUSM_ERRL — Raw Status of Error from MSS_VBUSM_SAFETY_L0_ERRAGG. Set irrespective if the Interupt is masked or unmasked in MSS_VBUSM_SAFETY_L0_ERRAGG_ERRAGG_MASK
  [7] CR5B1_RD_VBUSM_ERRL — Raw Status of Error from MSS_VBUSM_SAFETY_L0_ERRAGG. Set irrespective if the Interupt is masked or unmasked in MSS_VBUSM_SAFETY_L0_ERRAGG_ERRAGG_MASK
  [6] CR5A1_RD_VBUSM_ERRL — Raw Status of Error from MSS_VBUSM_SAFETY_L0_ERRAGG. Set irrespective if the Interupt is masked or unmasked in MSS_VBUSM_SAFETY_L0_ERRAGG_ERRAGG_MASK
  [5] CR5B0_SLV_VBUSM_ERRL — Raw Status of Error from MSS_VBUSM_SAFETY_L0_ERRAGG. Set irrespective if the Interupt is masked or unmasked in MSS_VBUSM_SAFETY_L0_ERRAGG_ERRAGG_MASK
  [4] CR5A0_SLV_VBUSM_ERRL — Raw Status of Error from MSS_VBUSM_SAFETY_L0_ERRAGG. Set irrespective if the Interupt is masked or unmasked in MSS_VBUSM_SAFETY_L0_ERRAGG_ERRAGG_MASK
  [3] CR5B0_WR_VBUSM_ERRL — Raw Status of Error from MSS_VBUSM_SAFETY_L0_ERRAGG. Set irrespective if the Interupt is masked or unmasked in MSS_VBUSM_SAFETY_L0_ERRAGG_ERRAGG_MASK
  [2] CR5A0_WR_VBUSM_ERRL — Raw Status of Error from MSS_VBUSM_SAFETY_L0_ERRAGG. Set irrespective if the Interupt is masked or unmasked in MSS_VBUSM_SAFETY_L0_ERRAGG_ERRAGG_MASK
  [1] CR5B0_RD_VBUSM_ERRL — Raw Status of Error from MSS_VBUSM_SAFETY_L0_ERRAGG. Set irrespective if the Interupt is masked or unmasked in MSS_VBUSM_SAFETY_L0_ERRAGG_ERRAGG_MASK
  [0] CR5A0_RD_VBUSM_ERRL — Raw Status of Error from MSS_VBUSM_SAFETY_L0_ERRAGG. Set irrespective if the Interupt is masked or unmasked in MSS_VBUSM_SAFETY_L0_ERRAGG_ERRAGG_MASK
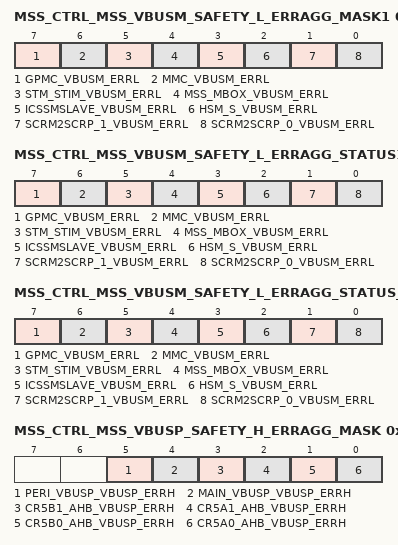
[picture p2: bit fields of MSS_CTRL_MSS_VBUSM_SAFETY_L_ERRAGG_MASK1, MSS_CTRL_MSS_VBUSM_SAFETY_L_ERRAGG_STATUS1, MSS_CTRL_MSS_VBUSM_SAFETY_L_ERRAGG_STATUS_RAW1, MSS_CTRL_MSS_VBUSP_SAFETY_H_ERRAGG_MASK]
0x18864 MSS_CTRL_MSS_VBUSM_SAFETY_L_ERRAGG_MASK1 8-bit rw
  [7] GPMC_VBUSM_ERRL — Mask Error from MSS_VBUSM_SAFETY_L1_ERRAGG to aggregated Error MSS_VBUSM_SAFETY_L1_ERRAGG_ERRAGG1 : Error is Masked0 : Error is Unmasked
  [6] MMC_VBUSM_ERRL — Mask Error from MSS_VBUSM_SAFETY_L1_ERRAGG to aggregated Error MSS_VBUSM_SAFETY_L1_ERRAGG_ERRAGG1 : Error is Masked0 : Error is Unmasked
  [5] STM_STIM_VBUSM_ERRL — Mask Error from MSS_VBUSM_SAFETY_L1_ERRAGG to aggregated Error MSS_VBUSM_SAFETY_L1_ERRAGG_ERRAGG1 : Error is Masked0 : Error is Unmasked
  [4] MSS_MBOX_VBUSM_ERRL — Mask Error from MSS_VBUSM_SAFETY_L1_ERRAGG to aggregated Error MSS_VBUSM_SAFETY_L1_ERRAGG_ERRAGG1 : Error is Masked0 : Error is Unmasked
  [3] ICSSMSLAVE_VBUSM_ERRL — Mask Error from MSS_VBUSM_SAFETY_L1_ERRAGG to aggregated Error MSS_VBUSM_SAFETY_L1_ERRAGG_ERRAGG1 : Error is Masked0 : Error is Unmasked
  [2] HSM_S_VBUSM_ERRL — Mask Error from MSS_VBUSM_SAFETY_L1_ERRAGG to aggregated Error MSS_VBUSM_SAFETY_L1_ERRAGG_ERRAGG1 : Error is Masked0 : Error is Unmasked
  [1] SCRM2SCRP_1_VBUSM_ERRL — Mask Error from MSS_VBUSM_SAFETY_L1_ERRAGG to aggregated Error MSS_VBUSM_SAFETY_L1_ERRAGG_ERRAGG1 : Error is Masked0 : Error is Unmasked
  [0] SCRM2SCRP_0_VBUSM_ERRL — Mask Error from MSS_VBUSM_SAFETY_L1_ERRAGG to aggregated Error MSS_VBUSM_SAFETY_L1_ERRAGG_ERRAGG1 : Error is Masked0 : Error is Unmasked
0x18868 MSS_CTRL_MSS_VBUSM_SAFETY_L_ERRAGG_STATUS1 8-bit rw
  [7] GPMC_VBUSM_ERRL — Status of Error from MSS_VBUSM_SAFETY_L1_ERRAGG. Set only if Interupt is unmasked in MSS_VBUSM_SAFETY_L1_ERRAGG_ERRAGG_MASKWrie 0x1 to clear this Error.
  [6] MMC_VBUSM_ERRL — Status of Error from MSS_VBUSM_SAFETY_L1_ERRAGG. Set only if Interupt is unmasked in MSS_VBUSM_SAFETY_L1_ERRAGG_ERRAGG_MASKWrie 0x1 to clear this Error.
  [5] STM_STIM_VBUSM_ERRL — Status of Error from MSS_VBUSM_SAFETY_L1_ERRAGG. Set only if Interupt is unmasked in MSS_VBUSM_SAFETY_L1_ERRAGG_ERRAGG_MASKWrie 0x1 to clear this Error.
  [4] MSS_MBOX_VBUSM_ERRL — Status of Error from MSS_VBUSM_SAFETY_L1_ERRAGG. Set only if Interupt is unmasked in MSS_VBUSM_SAFETY_L1_ERRAGG_ERRAGG_MASKWrie 0x1 to clear this Error.
  [3] ICSSMSLAVE_VBUSM_ERRL — Status of Error from MSS_VBUSM_SAFETY_L1_ERRAGG. Set only if Interupt is unmasked in MSS_VBUSM_SAFETY_L1_ERRAGG_ERRAGG_MASKWrie 0x1 to clear this Error.
  [2] HSM_S_VBUSM_ERRL — Status of Error from MSS_VBUSM_SAFETY_L1_ERRAGG. Set only if Interupt is unmasked in MSS_VBUSM_SAFETY_L1_ERRAGG_ERRAGG_MASKWrie 0x1 to clear this Error.
  [1] SCRM2SCRP_1_VBUSM_ERRL — Status of Error from MSS_VBUSM_SAFETY_L1_ERRAGG. Set only if Interupt is unmasked in MSS_VBUSM_SAFETY_L1_ERRAGG_ERRAGG_MASKWrie 0x1 to clear this Error.
  [0] SCRM2SCRP_0_VBUSM_ERRL — Status of Error from MSS_VBUSM_SAFETY_L1_ERRAGG. Set only if Interupt is unmasked in MSS_VBUSM_SAFETY_L1_ERRAGG_ERRAGG_MASKWrie 0x1 to clear this Error.
0x1886C MSS_CTRL_MSS_VBUSM_SAFETY_L_ERRAGG_STATUS_RAW1 8-bit rw
  [7] GPMC_VBUSM_ERRL — Raw Status of Error from MSS_VBUSM_SAFETY_L1_ERRAGG. Set irrespective if the Interupt is masked or unmasked in MSS_VBUSM_SAFETY_L1_ERRAGG_ERRAGG_MASK
  [6] MMC_VBUSM_ERRL — Raw Status of Error from MSS_VBUSM_SAFETY_L1_ERRAGG. Set irrespective if the Interupt is masked or unmasked in MSS_VBUSM_SAFETY_L1_ERRAGG_ERRAGG_MASK
  [5] STM_STIM_VBUSM_ERRL — Raw Status of Error from MSS_VBUSM_SAFETY_L1_ERRAGG. Set irrespective if the Interupt is masked or unmasked in MSS_VBUSM_SAFETY_L1_ERRAGG_ERRAGG_MASK
  [4] MSS_MBOX_VBUSM_ERRL — Raw Status of Error from MSS_VBUSM_SAFETY_L1_ERRAGG. Set irrespective if the Interupt is masked or unmasked in MSS_VBUSM_SAFETY_L1_ERRAGG_ERRAGG_MASK
  [3] ICSSMSLAVE_VBUSM_ERRL — Raw Status of Error from MSS_VBUSM_SAFETY_L1_ERRAGG. Set irrespective if the Interupt is masked or unmasked in MSS_VBUSM_SAFETY_L1_ERRAGG_ERRAGG_MASK
  [2] HSM_S_VBUSM_ERRL — Raw Status of Error from MSS_VBUSM_SAFETY_L1_ERRAGG. Set irrespective if the Interupt is masked or unmasked in MSS_VBUSM_SAFETY_L1_ERRAGG_ERRAGG_MASK
  [1] SCRM2SCRP_1_VBUSM_ERRL — Raw Status of Error from MSS_VBUSM_SAFETY_L1_ERRAGG. Set irrespective if the Interupt is masked or unmasked in MSS_VBUSM_SAFETY_L1_ERRAGG_ERRAGG_MASK
  [0] SCRM2SCRP_0_VBUSM_ERRL — Raw Status of Error from MSS_VBUSM_SAFETY_L1_ERRAGG. Set irrespective if the Interupt is masked or unmasked in MSS_VBUSM_SAFETY_L1_ERRAGG_ERRAGG_MASK
0x18874 MSS_CTRL_MSS_VBUSP_SAFETY_H_ERRAGG_MASK 8-bit rw
  [5] PERI_VBUSP_VBUSP_ERRH — Mask Error from MSS_VBUSP_SAFETY_H_ERRAGG to aggregated Error MSS_VBUSP_SAFETY_H_ERRAGG_ERRAGG1 : Error is Masked0 : Error is Unmasked
  [4] MAIN_VBUSP_VBUSP_ERRH — Mask Error from MSS_VBUSP_SAFETY_H_ERRAGG to aggregated Error MSS_VBUSP_SAFETY_H_ERRAGG_ERRAGG1 : Error is Masked0 : Error is Unmasked
  [3] CR5B1_AHB_VBUSP_ERRH — Mask Error from MSS_VBUSP_SAFETY_H_ERRAGG to aggregated Error MSS_VBUSP_SAFETY_H_ERRAGG_ERRAGG1 : Error is Masked0 : Error is Unmasked
  [2] CR5A1_AHB_VBUSP_ERRH — Mask Error from MSS_VBUSP_SAFETY_H_ERRAGG to aggregated Error MSS_VBUSP_SAFETY_H_ERRAGG_ERRAGG1 : Error is Masked0 : Error is Unmasked
  [1] CR5B0_AHB_VBUSP_ERRH — Mask Error from MSS_VBUSP_SAFETY_H_ERRAGG to aggregated Error MSS_VBUSP_SAFETY_H_ERRAGG_ERRAGG1 : Error is Masked0 : Error is Unmasked
  [0] CR5A0_AHB_VBUSP_ERRH — Mask Error from MSS_VBUSP_SAFETY_H_ERRAGG to aggregated Error MSS_VBUSP_SAFETY_H_ERRAGG_ERRAGG1 : Error is Masked0 : Error is Unmasked
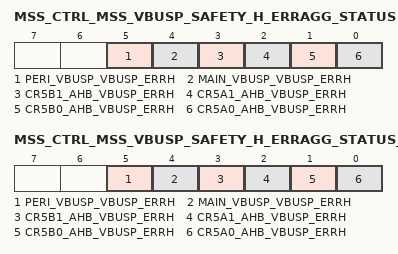
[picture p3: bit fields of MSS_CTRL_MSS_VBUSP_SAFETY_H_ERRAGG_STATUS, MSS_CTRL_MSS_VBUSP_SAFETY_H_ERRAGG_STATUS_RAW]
0x18878 MSS_CTRL_MSS_VBUSP_SAFETY_H_ERRAGG_STATUS 8-bit rw
  [5] PERI_VBUSP_VBUSP_ERRH — Status of Error from MSS_VBUSP_SAFETY_H_ERRAGG. Set only if Interupt is unmasked in MSS_VBUSP_SAFETY_H_ERRAGG_ERRAGG_MASKWrie 0x1 to clear this Error.
  [4] MAIN_VBUSP_VBUSP_ERRH — Status of Error from MSS_VBUSP_SAFETY_H_ERRAGG. Set only if Interupt is unmasked in MSS_VBUSP_SAFETY_H_ERRAGG_ERRAGG_MASKWrie 0x1 to clear this Error.
  [3] CR5B1_AHB_VBUSP_ERRH — Status of Error from MSS_VBUSP_SAFETY_H_ERRAGG. Set only if Interupt is unmasked in MSS_VBUSP_SAFETY_H_ERRAGG_ERRAGG_MASKWrie 0x1 to clear this Error.
  [2] CR5A1_AHB_VBUSP_ERRH — Status of Error from MSS_VBUSP_SAFETY_H_ERRAGG. Set only if Interupt is unmasked in MSS_VBUSP_SAFETY_H_ERRAGG_ERRAGG_MASKWrie 0x1 to clear this Error.
  [1] CR5B0_AHB_VBUSP_ERRH — Status of Error from MSS_VBUSP_SAFETY_H_ERRAGG. Set only if Interupt is unmasked in MSS_VBUSP_SAFETY_H_ERRAGG_ERRAGG_MASKWrie 0x1 to clear this Error.
  [0] CR5A0_AHB_VBUSP_ERRH — Status of Error from MSS_VBUSP_SAFETY_H_ERRAGG. Set only if Interupt is unmasked in MSS_VBUSP_SAFETY_H_ERRAGG_ERRAGG_MASKWrie 0x1 to clear this Error.
0x1887C MSS_CTRL_MSS_VBUSP_SAFETY_H_ERRAGG_STATUS_RAW 8-bit rw
  [5] PERI_VBUSP_VBUSP_ERRH — Raw Status of Error from MSS_VBUSP_SAFETY_H_ERRAGG. Set irrespective if the Interupt is masked or unmasked in MSS_VBUSP_SAFETY_H_ERRAGG_ERRAGG_MASK
  [4] MAIN_VBUSP_VBUSP_ERRH — Raw Status of Error from MSS_VBUSP_SAFETY_H_ERRAGG. Set irrespective if the Interupt is masked or unmasked in MSS_VBUSP_SAFETY_H_ERRAGG_ERRAGG_MASK
  [3] CR5B1_AHB_VBUSP_ERRH — Raw Status of Error from MSS_VBUSP_SAFETY_H_ERRAGG. Set irrespective if the Interupt is masked or unmasked in MSS_VBUSP_SAFETY_H_ERRAGG_ERRAGG_MASK
  [2] CR5A1_AHB_VBUSP_ERRH — Raw Status of Error from MSS_VBUSP_SAFETY_H_ERRAGG. Set irrespective if the Interupt is masked or unmasked in MSS_VBUSP_SAFETY_H_ERRAGG_ERRAGG_MASK
  [1] CR5B0_AHB_VBUSP_ERRH — Raw Status of Error from MSS_VBUSP_SAFETY_H_ERRAGG. Set irrespective if the Interupt is masked or unmasked in MSS_VBUSP_SAFETY_H_ERRAGG_ERRAGG_MASK
  [0] CR5A0_AHB_VBUSP_ERRH — Raw Status of Error from MSS_VBUSP_SAFETY_H_ERRAGG. Set irrespective if the Interupt is masked or unmasked in MSS_VBUSP_SAFETY_H_ERRAGG_ERRAGG_MASK
